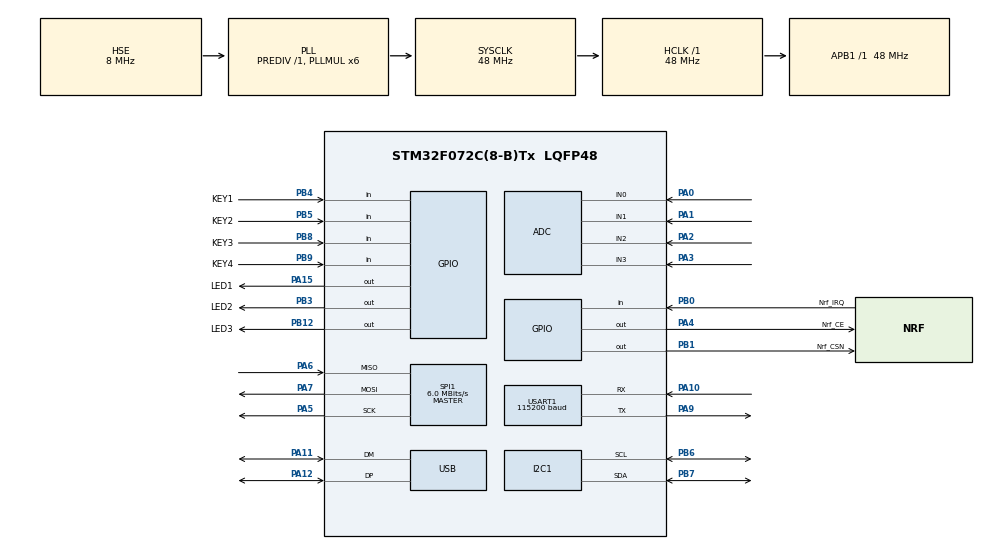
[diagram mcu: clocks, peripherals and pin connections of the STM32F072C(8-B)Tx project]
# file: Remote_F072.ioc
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ADC.Channel-IN1=ADC_CHANNEL_1
ADC.Channel-IN2=ADC_CHANNEL_2
ADC.Channel-IN3=ADC_CHANNEL_3
ADC.SamplingTime-0\#ChannelRegularConversion=ADC_SAMPLETIME_239CYCLES_5
FREERTOS.Tasks01=defaultTask,0,128,StartDefaultTask,Default,NULL,Dynamic,NULL,NULL;myTask_ADC,2,128,StartTask_ADC,Default,NULL,Dynamic,NULL,NULL;myTask_Nrf,0,128,StartTask_NRF,Default,NULL,Dynamic,NULL,NULL;myTask_LED,-2,128,StartTask_LED,Default,NULL,Dynamic,NULL,NULL;myTask_OLED,-2,128,StartTask_OLED,Default,NULL,Dynamic,NULL,NULL;myTask_Key,0,128,StartTask_KEY,Default,NULL,Dynamic,NULL,NULL
FREERTOS.Timers01=myTimer01,Callback01,osTimerPeriodic,Default,NULL,Dynamic,NULL
FREERTOS.configGENERATE_RUN_TIME_STATS=0
FREERTOS.configLIBRARY_LOWEST_INTERRUPT_PRIORITY=3
FREERTOS.configLIBRARY_MAX_SYSCALL_INTERRUPT_PRIORITY=1
FREERTOS.configTOTAL_HEAP_SIZE=10240
FREERTOS.configUSE_TIMERS=1
I2C1.Speed=100
I2C1.Timing=0x20303E5D
Mcu.Family=STM32F0
Mcu.Name=STM32F072C(8-B)Tx
Mcu.Package=LQFP48
PA0.Mode=IN0
PA0.Signal=ADC_IN0
PA1.Mode=IN1
PA1.Signal=ADC_IN1
PA10.Mode=Asynchronous
PA10.Signal=USART1_RX
PA11.Mode=Device
PA11.Signal=USB_DM
PA12.Mode=Device
PA12.Signal=USB_DP
PA13.Mode=Serial_Wire
PA13.Signal=SYS_SWDIO
PA14.Mode=Serial_Wire
PA14.Signal=SYS_SWCLK
PA15.GPIO_Label=LED1
PA15.GPIO_ModeDefaultOutputPP=GPIO_MODE_OUTPUT_PP
PA15.GPIO_PuPd=GPIO_PULLUP
PA15.GPIO_Speed=GPIO_SPEED_FREQ_HIGH
PA15.PinState=GPIO_PIN_SET
PA15.Signal=GPIO_Output
PA2.Mode=IN2
PA2.Signal=ADC_IN2
PA3.Mode=IN3
PA3.Signal=ADC_IN3
PA4.GPIO_Label=Nrf_CE
PA4.GPIO_PuPd=GPIO_PULLUP
PA4.GPIO_Speed=GPIO_SPEED_FREQ_HIGH
PA4.Signal=GPIO_Output
PA5.Mode=Full_Duplex_Master
PA5.Signal=SPI1_SCK
PA6.Mode=Full_Duplex_Master
PA6.Signal=SPI1_MISO
PA7.Mode=Full_Duplex_Master
PA7.Signal=SPI1_MOSI
PA9.Mode=Asynchronous
PA9.Signal=USART1_TX
PB0.GPIO_Label=Nrf_IRQ
PB0.GPIO_PuPd=GPIO_PULLUP
PB0.Signal=GPIO_Input
PB1.GPIO_Label=Nrf_CSN
PB1.GPIO_ModeDefaultOutputPP=GPIO_MODE_OUTPUT_PP
PB1.GPIO_PuPd=GPIO_PULLUP
PB1.GPIO_Speed=GPIO_SPEED_FREQ_HIGH
PB1.PinState=GPIO_PIN_SET
PB1.Signal=GPIO_Output
PB12.GPIO_Label=LED3
PB12.GPIO_PuPd=GPIO_PULLUP
PB12.GPIO_Speed=GPIO_SPEED_FREQ_HIGH
PB12.Signal=GPIO_Output
PB3.GPIO_Label=LED2
PB3.GPIO_ModeDefaultOutputPP=GPIO_MODE_OUTPUT_PP
PB3.GPIO_PuPd=GPIO_PULLUP
PB3.GPIO_Speed=GPIO_SPEED_FREQ_HIGH
PB3.PinState=GPIO_PIN_RESET
PB3.Signal=GPIO_Output
PB4.GPIO_Label=KEY1
PB4.GPIO_PuPd=GPIO_PULLDOWN
PB4.Signal=GPIO_Input
PB5.GPIO_Label=KEY2
PB5.GPIO_PuPd=GPIO_PULLDOWN
PB5.Signal=GPIO_Input
PB6.Mode=I2C
PB6.Signal=I2C1_SCL
PB7.Mode=I2C
PB7.Signal=I2C1_SDA
PB8.GPIO_Label=KEY3
PB8.GPIO_PuPd=GPIO_PULLDOWN
PB8.Signal=GPIO_Input
PB9.GPIO_Label=KEY4
PB9.GPIO_PuPd=GPIO_PULLDOWN
PB9.Signal=GPIO_Input
PF0-OSC_IN.Mode=HSE-External-Oscillator
PF0-OSC_IN.Signal=RCC_OSC_IN
PF1-OSC_OUT.Mode=HSE-External-Oscillator
PF1-OSC_OUT.Signal=RCC_OSC_OUT
ProjectManager.HeapSize=0x200
ProjectManager.StackSize=0x400
ProjectManager.TargetToolchain=MDK-ARM V5
RCC.AHBFreq_Value=48000000
RCC.APB1Freq_Value=48000000
RCC.APB1TimFreq_Value=48000000
RCC.HCLKFreq_Value=48000000
RCC.I2c1ClockSelection=RCC_I2C1CLKSOURCE_SYSCLK
RCC.PLLMUL=RCC_PLL_MUL6
RCC.PLLSourceVirtual=RCC_PLLSOURCE_HSE
RCC.SYSCLKFreq_VALUE=48000000
RCC.SYSCLKSource=RCC_SYSCLKSOURCE_PLLCLK
SPI1.BaudRatePrescaler=SPI_BAUDRATEPRESCALER_8
SPI1.CLKPhase=SPI_PHASE_2EDGE
SPI1.CLKPolarity=SPI_POLARITY_HIGH
SPI1.CalculateBaudRate=6.0 MBits/s
SPI1.DataSize=SPI_DATASIZE_8BIT
SPI1.Direction=SPI_DIRECTION_2LINES
SPI1.Mode=SPI_MODE_MASTER
SPI1.VirtualType=VM_MASTER
USART1.BaudRate=115200
USART1.VirtualMode-Asynchronous=VM_ASYNC
USB.ep0_mps=DEP0CTL_MPS_8
VP_FREERTOS_VS_ENABLE.Mode=Enabled
board=custom

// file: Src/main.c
/**
  ******************************************************************************
  * @file           : main.c
  * @brief          : Main program body
  ******************************************************************************
  * This notice applies to any and all portions of this file
  * that are not between comment pairs USER CODE BEGIN and
  * USER CODE END. Other portions of this file, whether
  * inserted by the user or by software development tools
  * are owned by their respective copyright owners.
  *
  * Copyright (c) 2018 STMicroelectronics International N.V.
  * All rights reserved.
  *
  * Redistribution and use in source and binary forms, with or without
  * modification, are permitted, provided that the following conditions are met:
  *
  * 1. Redistribution of source code must retain the above copyright notice,
  *    this list of conditions and the following disclaimer.
  * 2. Redistributions in binary form must reproduce the above copyright notice,
  *    this list of conditions and the following disclaimer in the documentation
  *    and/or other materials provided with the distribution.
  * 3. Neither the name of STMicroelectronics nor the names of other
  *    contributors to this software may be used to endorse or promote products
  *    derived from this software without specific written permission.
  * 4. This software, including modifications and/or derivative works of this
  *    software, must execute solely and exclusively on microcontroller or
  *    microprocessor devices manufactured by or for STMicroelectronics.
  * 5. Redistribution and use of this software other than as permitted under
  *    this license is void and will automatically terminate your rights under
  *    this license.
  *
  * THIS SOFTWARE IS PROVIDED BY STMICROELECTRONICS AND CONTRIBUTORS "AS IS"
  * AND ANY EXPRESS, IMPLIED OR STATUTORY WARRANTIES, INCLUDING, BUT NOT
  * LIMITED TO, THE IMPLIED WARRANTIES OF MERCHANTABILITY, FITNESS FOR A
  * PARTICULAR PURPOSE AND NON-INFRINGEMENT OF THIRD PARTY INTELLECTUAL PROPERTY
  * RIGHTS ARE DISCLAIMED TO THE FULLEST EXTENT PERMITTED BY LAW. IN NO EVENT
  * SHALL STMICROELECTRONICS OR CONTRIBUTORS BE LIABLE FOR ANY DIRECT, INDIRECT,
  * INCIDENTAL, SPECIAL, EXEMPLARY, OR CONSEQUENTIAL DAMAGES (INCLUDING, BUT NOT
  * LIMITED TO, PROCUREMENT OF SUBSTITUTE GOODS OR SERVICES; LOSS OF USE, DATA,
  * OR PROFITS; OR BUSINESS INTERRUPTION) HOWEVER CAUSED AND ON ANY THEORY OF
  * LIABILITY, WHETHER IN CONTRACT, STRICT LIABILITY, OR TORT (INCLUDING
  * NEGLIGENCE OR OTHERWISE) ARISING IN ANY WAY OUT OF THE USE OF THIS SOFTWARE,
  * EVEN IF ADVISED OF THE POSSIBILITY OF SUCH DAMAGE.
  *
  ******************************************************************************
  */
#include "main.h"
#include "stm32f0xx_hal.h"
#include "cmsis_os.h"
#include "adc.h"
#include "i2c.h"
#include "spi.h"
#include "usart.h"
#include "usb.h"
#include "gpio.h"

/* USER CODE BEGIN PV */
/* Private variables ---------------------------------------------------------*/

/* USER CODE END PV */

void SystemClock_Config(void);
void MX_FREERTOS_Init(void);

/* USER CODE BEGIN PFP */
/* Private function prototypes -----------------------------------------------*/

/* USER CODE END PFP */

int main(void)
{

  /* MCU Configuration----------------------------------------------------------*/

  /* Reset of all peripherals, Initializes the Flash interface and the Systick. */
  HAL_Init();

  /* Configure the system clock */
  SystemClock_Config();

  /* Initialize all configured peripherals */
  MX_GPIO_Init();
  MX_I2C1_Init();
  MX_SPI1_Init();
  MX_USB_PCD_Init();
  MX_USART1_UART_Init();
  MX_ADC_Init();

  /* Call init function for freertos objects (in freertos.c) */
  MX_FREERTOS_Init();

  /* Start scheduler */
  osKernelStart();

  /* We should never get here as control is now taken by the scheduler */

  /* Infinite loop */
  while (1)
  {

  }

}

void SystemClock_Config(void)
{

  RCC_OscInitTypeDef RCC_OscInitStruct;
  RCC_ClkInitTypeDef RCC_ClkInitStruct;
  RCC_PeriphCLKInitTypeDef PeriphClkInit;

    /**Initializes the CPU, AHB and APB busses clocks
    */
  RCC_OscInitStruct.OscillatorType = RCC_OSCILLATORTYPE_HSI14|RCC_OSCILLATORTYPE_HSI48
                              |RCC_OSCILLATORTYPE_HSE;
  RCC_OscInitStruct.HSEState = RCC_HSE_ON;
  RCC_OscInitStruct.HSI48State = RCC_HSI48_ON;
  RCC_OscInitStruct.HSI14State = RCC_HSI14_ON;
  RCC_OscInitStruct.HSI14CalibrationValue = 16;
  RCC_OscInitStruct.PLL.PLLState = RCC_PLL_ON;
  RCC_OscInitStruct.PLL.PLLSource = RCC_PLLSOURCE_HSE;
  RCC_OscInitStruct.PLL.PLLMUL = RCC_PLL_MUL6;
  RCC_OscInitStruct.PLL.PREDIV = RCC_PREDIV_DIV1;
  if (HAL_RCC_OscConfig(&RCC_OscInitStruct) != HAL_OK)
  {
    _Error_Handler(__FILE__, __LINE__);
  }

    /**Initializes the CPU, AHB and APB busses clocks
    */
  RCC_ClkInitStruct.ClockType = RCC_CLOCKTYPE_HCLK|RCC_CLOCKTYPE_SYSCLK
                              |RCC_CLOCKTYPE_PCLK1;
  RCC_ClkInitStruct.SYSCLKSource = RCC_SYSCLKSOURCE_PLLCLK;
  RCC_ClkInitStruct.AHBCLKDivider = RCC_SYSCLK_DIV1;
  RCC_ClkInitStruct.APB1CLKDivider = RCC_HCLK_DIV1;

  if (HAL_RCC_ClockConfig(&RCC_ClkInitStruct, FLASH_LATENCY_1) != HAL_OK)
  {
    _Error_Handler(__FILE__, __LINE__);
  }

  PeriphClkInit.PeriphClockSelection = RCC_PERIPHCLK_USB|RCC_PERIPHCLK_USART1
                              |RCC_PERIPHCLK_I2C1;
  PeriphClkInit.Usart1ClockSelection = RCC_USART1CLKSOURCE_PCLK1;
  PeriphClkInit.I2c1ClockSelection = RCC_I2C1CLKSOURCE_SYSCLK;
  PeriphClkInit.UsbClockSelection = RCC_USBCLKSOURCE_HSI48;

  if (HAL_RCCEx_PeriphCLKConfig(&PeriphClkInit) != HAL_OK)
  {
    _Error_Handler(__FILE__, __LINE__);
  }

    /**Configure the Systick interrupt time
    */
  HAL_SYSTICK_Config(HAL_RCC_GetHCLKFreq()/1000);

    /**Configure the Systick
    */
  HAL_SYSTICK_CLKSourceConfig(SYSTICK_CLKSOURCE_HCLK);

  /* SysTick_IRQn interrupt configuration */
  HAL_NVIC_SetPriority(SysTick_IRQn, 3, 0);
}

void _Error_Handler(char *file, int line)
{
  while(1)
  {
  }
}

/************************ (C) COPYRIGHT STMicroelectronics *****END OF FILE****/

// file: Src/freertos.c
/**
  ******************************************************************************
  * File Name          : freertos.c
  * Description        : Code for freertos applications
  ******************************************************************************
  * This notice applies to any and all portions of this file
  * that are not between comment pairs USER CODE BEGIN and
  * USER CODE END. Other portions of this file, whether
  * inserted by the user or by software development tools
  * are owned by their respective copyright owners.
  *
  * Copyright (c) 2018 STMicroelectronics International N.V.
  * All rights reserved.
  *
  * Redistribution and use in source and binary forms, with or without
  * modification, are permitted, provided that the following conditions are met:
  *
  * 1. Redistribution of source code must retain the above copyright notice,
  *    this list of conditions and the following disclaimer.
  * 2. Redistributions in binary form must reproduce the above copyright notice,
  *    this list of conditions and the following disclaimer in the documentation
  *    and/or other materials provided with the distribution.
  * 3. Neither the name of STMicroelectronics nor the names of other
  *    contributors to this software may be used to endorse or promote products
  *    derived from this software without specific written permission.
  * 4. This software, including modifications and/or derivative works of this
  *    software, must execute solely and exclusively on microcontroller or
  *    microprocessor devices manufactured by or for STMicroelectronics.
  * 5. Redistribution and use of this software other than as permitted under
  *    this license is void and will automatically terminate your rights under
  *    this license.
  *
  * THIS SOFTWARE IS PROVIDED BY STMICROELECTRONICS AND CONTRIBUTORS "AS IS"
  * AND ANY EXPRESS, IMPLIED OR STATUTORY WARRANTIES, INCLUDING, BUT NOT
  * LIMITED TO, THE IMPLIED WARRANTIES OF MERCHANTABILITY, FITNESS FOR A
  * PARTICULAR PURPOSE AND NON-INFRINGEMENT OF THIRD PARTY INTELLECTUAL PROPERTY
  * RIGHTS ARE DISCLAIMED TO THE FULLEST EXTENT PERMITTED BY LAW. IN NO EVENT
  * SHALL STMICROELECTRONICS OR CONTRIBUTORS BE LIABLE FOR ANY DIRECT, INDIRECT,
  * INCIDENTAL, SPECIAL, EXEMPLARY, OR CONSEQUENTIAL DAMAGES (INCLUDING, BUT NOT
  * LIMITED TO, PROCUREMENT OF SUBSTITUTE GOODS OR SERVICES; LOSS OF USE, DATA,
  * OR PROFITS; OR BUSINESS INTERRUPTION) HOWEVER CAUSED AND ON ANY THEORY OF
  * LIABILITY, WHETHER IN CONTRACT, STRICT LIABILITY, OR TORT (INCLUDING
  * NEGLIGENCE OR OTHERWISE) ARISING IN ANY WAY OUT OF THE USE OF THIS SOFTWARE,
  * EVEN IF ADVISED OF THE POSSIBILITY OF SUCH DAMAGE.
  *
  ******************************************************************************
  */

#include "FreeRTOS.h"
#include "task.h"
#include "cmsis_os.h"

/* USER CODE BEGIN Includes */
#include "stm32f0xx_hal.h"
/* USER CODE END Includes */

osThreadId defaultTaskHandle;
osThreadId myTask_ADCHandle;
osThreadId myTask_NrfHandle;
osThreadId myTask_LEDHandle;
osThreadId myTask_OLEDHandle;
osThreadId myTask_KeyHandle;
osTimerId myTimer01Handle;

void StartDefaultTask(void const * argument);
void StartTask_ADC(void const * argument);
void StartTask_NRF(void const * argument);
void StartTask_LED(void const * argument);
void StartTask_OLED(void const * argument);
void StartTask_KEY(void const * argument);
void Callback01(void const * argument);

void MX_FREERTOS_Init(void); /* (MISRA C 2004 rule 8.1) */

/* Hook prototypes */

/* Init FreeRTOS */

void MX_FREERTOS_Init(void) {

  /* Create the timer(s) */
  /* definition and creation of myTimer01 */
  osTimerDef(myTimer01, Callback01);
  myTimer01Handle = osTimerCreate(osTimer(myTimer01), osTimerPeriodic, NULL);

  /* USER CODE BEGIN RTOS_TIMERS */
  /* start timers, add new ones, ... */
  osStatus timerresult = osOK ;
  timerresult = osTimerStart(myTimer01Handle,1000) ;

  /* USER CODE END RTOS_TIMERS */

  /* Create the thread(s) */
  /* definition and creation of defaultTask */
  osThreadDef(defaultTask, StartDefaultTask, osPriorityNormal, 0, 128);
  defaultTaskHandle = osThreadCreate(osThread(defaultTask), NULL);

  /* definition and creation of myTask_ADC */
  osThreadDef(myTask_ADC, StartTask_ADC, osPriorityHigh, 0, 128);
  myTask_ADCHandle = osThreadCreate(osThread(myTask_ADC), NULL);

  /* definition and creation of myTask_Nrf */
  osThreadDef(myTask_Nrf, StartTask_NRF, osPriorityNormal, 0, 128);
  myTask_NrfHandle = osThreadCreate(osThread(myTask_Nrf), NULL);

  /* definition and creation of myTask_LED */
  osThreadDef(myTask_LED, StartTask_LED, osPriorityLow, 0, 128);
  myTask_LEDHandle = osThreadCreate(osThread(myTask_LED), NULL);

  /* definition and creation of myTask_OLED */
  osThreadDef(myTask_OLED, StartTask_OLED, osPriorityLow, 0, 128);
  myTask_OLEDHandle = osThreadCreate(osThread(myTask_OLED), NULL);

  /* definition and creation of myTask_Key */
  osThreadDef(myTask_Key, StartTask_KEY, osPriorityNormal, 0, 128);
  myTask_KeyHandle = osThreadCreate(osThread(myTask_Key), NULL);

}

/* StartDefaultTask function */
void StartDefaultTask(void const * argument)
{

  for(;;)
  {
    osDelay(1);
  }
}

/* StartTask_ADC function */
void StartTask_ADC(void const * argument)
{
  for(;;)
  {
    osDelay(1);
  }
}

/* StartTask_NRF function */
void StartTask_NRF(void const * argument)
{
  for(;;)
  {
    osDelay(1);
  }
}

/* StartTask_LED function */
void StartTask_LED(void const * argument)
{
  for(;;)
  {
    osDelay(1);
  }
}

/* StartTask_OLED function */
void StartTask_OLED(void const * argument)
{
  for(;;)
  {
    osDelay(1);
  }
}

/* StartTask_KEY function */
void StartTask_KEY(void const * argument)
{
  for(;;)
  {
    osDelay(1);
  }
}

/* Callback01 function */
void Callback01(void const * argument)
{
  /* USER CODE BEGIN Callback01 */
    HAL_GPIO_TogglePin(LED3_GPIO_Port, LED3_Pin);
  /* USER CODE END Callback01 */
}

/************************ (C) COPYRIGHT STMicroelectronics *****END OF FILE****/
